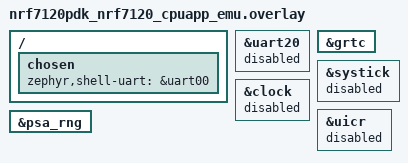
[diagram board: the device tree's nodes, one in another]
/ {
    chosen {
        zephyr,shell-uart = &uart00;
    };
};

&uart20 {
    status = "disabled";
};

&grtc {
    status = "okay";
};

&systick {
    status = "disabled";
};

&clock {
    status = "disabled";
};

&uicr {
    status = "disabled";
};

&psa_rng {
    status = "okay";
};
